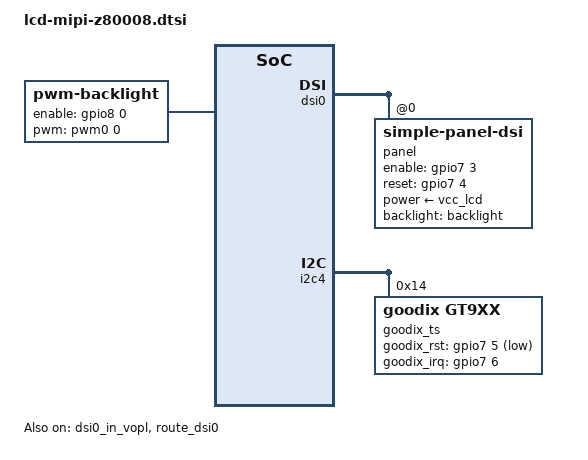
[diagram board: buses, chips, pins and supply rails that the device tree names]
/*
 * Copyright (C) 2018 9tripod, Inc.
 * arch/arm/boot/dts/lcd-mipi1024x600-WY070ML.dtsi
 * lcd model: sq080b331m 
 * resolution: 800x1280
 * mipi channel: single 
 */
/{
		backlight: backlight {
		compatible = "pwm-backlight";
		brightness-levels = <
			  0   1   2   3   4   5   6   7
			  8   9  10  11  12  13  14  15
			 16  17  18  19  20  21  22  23
			 24  25  26  27  28  29  30  31
			 32  33  34  35  36  37  38  39
			 40  41  42  43  44  45  46  47
			 48  49  50  51  52  53  54  55
			 56  57  58  59  60  61  62  63
			 64  65  66  67  68  69  70  71
			 72  73  74  75  76  77  78  79
			 80  81  82  83  84  85  86  87
			 88  89  90  91  92  93  94  95
			 96  97  98  99 100 101 102 103
			104 105 106 107 108 109 110 111
			112 113 114 115 116 117 118 119
			120 121 122 123 124 125 126 127
			128 129 130 131 132 133 134 135
			136 137 138 139 140 141 142 143
			144 145 146 147 148 149 150 151
			152 153 154 155 156 157 158 159
			160 161 162 163 164 165 166 167
			168 169 170 171 172 173 174 175
			176 177 178 179 180 181 182 183
			184 185 186 187 188 189 190 191
			192 193 194 195 196 197 198 199
			200 201 202 203 204 205 206 207
			208 209 210 211 212 213 214 215
			216 217 218 219 220 221 222 223
			224 225 226 227 228 229 230 231
			232 233 234 235 236 237 238 239
			240 241 242 243 244 245 246 247
			248 249 250 251 252 253 254 255>;
		default-brightness-level = <188>;
		enable-gpios = <&gpio8 0 GPIO_ACTIVE_HIGH>;
		pinctrl-names = "default";
		pinctrl-0 = <&bl_en>;
		pwms = <&pwm0 0 1000000 1>;
	};

	zx_config {
                compatible = "zx_config";
                system_rotate = "90";
                lcd_density = "160";
                language = "zh-CN";   //zh-CN //en-US
                time_zone = "Asia/Shanghai"; //Asia/Shanghai = +8   //Europe/London  = +1	//Africa/Casablanca	= +0;
                status = "okay";
	};
};

&dsi0 {
	status = "okay";
	rockchip,lane-rate = <680>;
	panel: panel {
		compatible = "simple-panel-dsi";
		reg = <0>;
		backlight = <&backlight>;
		enable-gpios = <&gpio7 3 GPIO_ACTIVE_HIGH>;
		reset-gpios = <&gpio7 4 GPIO_ACTIVE_HIGH>;
		power-supply = <&vcc_lcd>;
	dsi,flags = <(MIPI_DSI_MODE_VIDEO | MIPI_DSI_MODE_VIDEO_BURST |
			  MIPI_DSI_MODE_LPM | MIPI_DSI_MODE_EOT_PACKET)>;
	dsi,format = <MIPI_DSI_FMT_RGB888>;
	dsi,lanes = <4>;
	prepare-delay-ms = <30>;
	reset-delay-ms = <200>;
	init-delay-ms = <120>;
	enable-delay-ms = <120>;
	disable-delay-ms = <120>;
	unprepare-delay-ms = <20>;
		status = "okay";
		panel-init-sequence = [
				15 00 02 ee 50 	
				39 00 03 ea 85 55  
				15 00 02 30 00      
				39 00 03 90 90 d0  
				15 00 02 99 00 
				15 00 02 97 0c 
				15 00 02 23 00 
				15 00 02 24 a0 
				15 00 02 80 10 
				15 00 02 81 50 
				15 00 02 79 00 
				15 00 02 7a 20 
				15 00 02 7d 00 
				15 00 02 56 83 
				15 00 02 93 65 
				15 00 02 95 74 
				15 00 02 ee 60 
				15 00 02 21 01 
				15 00 02 25 73 
				15 00 02 27 22 
				15 00 02 28 12 
				39 00 03 29 8c a5 
				15 00 02 2c f9 
				15 00 02 30 01 
				15 00 02 32 d9 
				15 00 02 3a a4 
				15 00 02 3b 00 
				15 00 02 3C 20 
				39 00 03 3d 12 93 
				39 00 03 42 55 55 
				15 00 02 7f 24 
				15 00 02 80 24 
				15 00 02 86 20 
				15 00 02 89 20 
				15 00 02 91 11 
				15 00 02 92 11 
				15 00 02 93 9F 
				15 00 02 9a 00 
				39 00 03 9b 02 80 
				39 00 06 47 15 2d 36 40 46 
				39 00 06 5a 15 2d 36 40 46 
				39 00 06 4c 56 53 6a 55 56 
				39 00 06 5f 56 53 6a 55 56 
				39 00 06 51 5a 3f 53 4c 59 
				39 00 06 64 5a 3f 53 4c 59 
				39 00 05 56 59 63 6e 7f 
				39 00 05 69 59 63 6e 7f 
				15 00 02 ee 70 
				39 00 05 00 08 0b 00 01   
				39 00 05 04 0b 0f 55 01   
				39 00 05 08 0b 0e 55 01   
				39 00 03 0c 02 60 
				39 00 06 10 0a 0d 00 00 00  
 				39 00 05 15 00 1f 0d 0c   
				39 00 06 20 11 14 00 00 00  
 				39 00 05 25 00 1f 0d 0c   
				39 00 03 29 02 60 
				39 00 06 46 ff 00 00 00 40   
				15 00 02 4b 88  
				39 00 07 30 12 13 55 dd dd 3c 
				39 00 07 36 12 13 55 dd dd 3c 
				39 00 06 60 08 3c 3c 04 21 
 				39 00 06 65 20 3c 1a 18 3c 
				39 00 06 6a 16 14 3c 12 10 
				39 00 06 6f 00 3c 3c 3c 3c 
				39 00 03 74 3c 3c 
				39 00 06 80 09 3c 3c 05 21 
 				39 00 06 85 20 3c 1b 19 3c 
				39 00 06 8a 17 15 3c 13 11 
				39 00 06 8f 01 3c 3c 3c 3c 
				39 00 03 94 3c 3c 
				39 00 03 ea 00 00
				15 00 02 ee 00
				05 64 01 11
				05 68 01 29

		];

		panel-exit-sequence = [
			05 ff 01 28
			05 ff 01 10
		];
		disp_timings: display-timings {
			native-mode = <&timing0>;
			timing0: timing0 {
				clock-frequency = <73000000>;
				hactive = <800>;
				vactive = <1280>;
				hback-porch = <20>;//20
				hfront-porch = <120>;//32
				vback-porch = <8>;//10
				vfront-porch = <30>;//18
				hsync-len = <20>;//20
				vsync-len = <4>;//4
				hsync-active = <0>;
				vsync-active = <0>;
				de-active = <0>;
				pixelclk-active = <0>;
			};
		};
	};
};

&dsi0_in_vopl {
	status = "okay";
};

&dsi0_in_vopb {
	status = "disabled";
};
&route_dsi0 {
	status = "okay";
	connect = <&vopl_out_dsi0>;
};

&i2c4 {
        status = "okay";
        goodix_ts@14 {
		compatible = "goodix,gt9xx";
		reg = <0x14>;
		gtp_resolution_x = <800>;
		gtp_resolution_y = <1280>;
        	gtp_int_tarigger = <1>;
        	gtp_change_x2y = <0>;
        	gtp_overturn_x = <0>;
        	gtp_overturn_y = <0>;
        	gtp_send_cfg = <1>;
        	gtp_touch_wakeup = <1>;	
		goodix_rst_gpio = <&gpio7 5  GPIO_ACTIVE_LOW>;
		goodix_irq_gpio = <&gpio7 6 IRQ_TYPE_EDGE_RISING>;
	        goodix,cfg-group0 = [
			/*00 20 03 00 05 0A 0D 01 01 08
			28 05 50 32 03 05 00 00 00 00
			00 00 00 1C 1D 1E 14 8C 2C 0E
			17 15 31 0D 00 00 01 BA 03 1D
			00 00 00 00 00 03 64 32 00 00
			00 0F 55 94 C5 02 07 00 00 04
			94 12 00 6E 19 00 50 24 00 3C
			33 00 2F 48 00 2F 60 68 00 00
			F0 4A 3A FF FF 27 00 00 00 00
			00 00 00 00 00 00 00 00 00 00
			00 00 00 00 00 00 00 00 00 00
			00 00 02 04 06 08 0A 0C 0E 10
			12 14 16 18 1A 1C 00 00 00 00
			00 00 00 00 00 00 00 00 00 00
			00 00 28 26 24 22 21 20 1F 1E
			1D 1C 18 16 14 13 12 10 0F 0C
			0A 08 06 04 02 00 FF FF 00 00
			00 00 00 00 00 00 00 00 00 00
			00 00 00 00 45 01*/
			84 20 03 00 05 0A 0D 31 01 08
			28 05 50 32 03 05 00 00 00 00
			00 00 00 1C 1D 1E 14 8C 2C 0E
			17 15 31 0D 00 00 01 DB 03 1C
			00 2D 00 00 00 03 64 32 00 00
			00 0F 55 94 C5 02 07 00 00 04
			94 12 00 6E 19 00 50 24 00 3C
			33 00 2F 48 00 2F 60 68 00 00
			F0 4A 3A FF FF 27 00 00 00 00
			00 00 00 00 00 00 00 00 00 00
			00 00 00 00 00 00 00 00 00 00
			00 00 02 04 06 08 0A 0C 0E 10
			12 14 16 18 1A 1C 00 00 00 00
			00 00 00 00 00 00 00 00 00 00
			00 00 28 26 24 22 21 20 1F 1E
			1D 1C 18 16 14 13 12 10 0F 0C
			0A 08 06 04 02 00 FF FF 00 00
			00 00 00 00 00 00 00 00 00 00
			00 00 00 00 44 01];
	};
};

